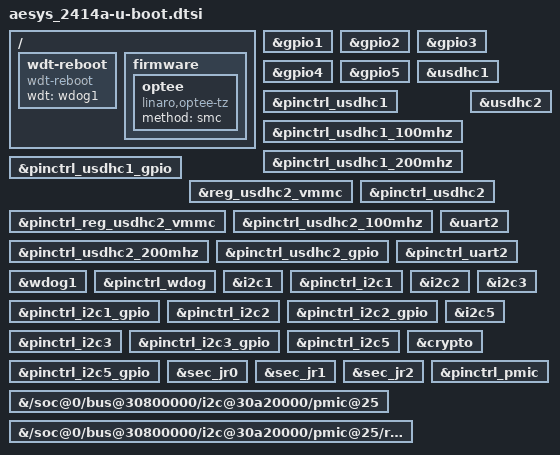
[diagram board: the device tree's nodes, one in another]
// SPDX-License-Identifier: GPL-2.0+

#include "imx8mp-sec-def.h"

#include "imx8mp-u-boot.dtsi"

/ {
	wdt-reboot {
		compatible = "wdt-reboot";
		wdt = <&wdog1>;
		bootph-pre-ram;
	};

	firmware {
		optee {
			compatible = "linaro,optee-tz";
			method = "smc";
		};
	};

	/* mcu_rdc {
		compatible = "imx8m,mcu_rdc";
			    * rdc config when MCU starts
			     * master
			     *   SDMA3p --> domain 1
			     *   SDMA3b --> domian 1
			     *   SDMA3_SPBA2  --> domian 1
			     * peripheral:
			     *   SAI3   --> Only Domian 1 can access
			     *   UART4  --> Only Domian 1 can access
			     *   GPT1   --> Only Domian 1 can access
			     *   SDMA3  --> Only Domian 1 can access
			     *   I2C3   --> Only Domian 1 can access
			     * memory:
			     *   TCM    --> Only Domian 1 can access (0x7E0000~0x81FFFF)
			     *   DDR    --> Only Domian 1 can access (0x80000000~0x81000000)
			     * end.
			     *
		start-config = <
			    RDC_MDA  RDC_MDA_SDMA3p DID1 0x0 0x0
			    RDC_MDA  RDC_MDA_ENET1_TX DID1 0x0 0x0
			    RDC_MDA  RDC_MDA_ENET1_RX DID1 0x0 0x0
			    RDC_MDA  RDC_MDA_SDMA3b DID1 0x0 0x0
			    RDC_MDA  RDC_MDA_SDMA3_SPBA2 DID1 0x0 0x0
			    RDC_PDAP RDC_PDAP_ENET1 PDAP_D0D1_ACCESS 0x0 0x0
			    RDC_PDAP RDC_PDAP_SAI3  PDAP_D1_ACCESS 0x0 0x0
			    RDC_PDAP RDC_PDAP_UART4 PDAP_D1_ACCESS 0x0 0x0
			    RDC_PDAP RDC_PDAP_GPT1  PDAP_D1_ACCESS 0x0 0x0
			    RDC_PDAP RDC_PDAP_SDMA3 PDAP_D1_ACCESS 0x0 0x0
			    RDC_PDAP RDC_PDAP_I2C3  PDAP_D1_ACCESS 0x0 0x0
			    RDC_MEM_REGION 22 TCM_START TCM_END MEM_D1_ACCESS
			    RDC_MEM_REGION 39 M4_DDR_START M4_DDR_END MEM_D1_ACCESS
			    0x0      0x0            0x0  0x0 0x0
			  >;
			     * rdc config when MCU stops
			     * memory:
			     *   TCM    --> domain 0/1 can access (0x7E0000~0x81FFFF)
			     *   DDR    --> domain 0/1 can access (0x80000000~0x81000000)
			     * end.
			     *
		stop-config = <
			    RDC_MEM_REGION 22 TCM_START TCM_END MEM_D0D1_ACCESS
			    RDC_MEM_REGION 39 M4_DDR_START M4_DDR_END MEM_D0D1_ACCESS
			    0x0      0x0            0x0  0x0 0x0
			  >;
	}; */
};

&gpio1 {
	bootph-pre-ram;
};

&gpio2 {
	bootph-pre-ram;
};

&gpio3 {
	bootph-pre-ram;
};

&gpio4 {
	bootph-pre-ram;
};

&gpio5 {
	bootph-pre-ram;
};

&usdhc1 {
	bootph-pre-ram;
};

&pinctrl_usdhc1 {
	bootph-pre-ram;
};

&pinctrl_usdhc1_100mhz {
	bootph-pre-ram;
};

&pinctrl_usdhc1_200mhz {
	bootph-pre-ram;
};

&pinctrl_usdhc1_gpio {
	bootph-pre-ram;
};

&usdhc2 {
	bootph-pre-ram;
};

&reg_usdhc2_vmmc {
	bootph-pre-ram;
};

&pinctrl_reg_usdhc2_vmmc {
	bootph-pre-ram;
};

&pinctrl_usdhc2 {
	bootph-pre-ram;
};

&pinctrl_usdhc2_100mhz {
	bootph-pre-ram;
};

&pinctrl_usdhc2_200mhz {
	bootph-pre-ram;
};

&pinctrl_usdhc2_gpio {
	bootph-pre-ram;
};

&uart2 {
	bootph-pre-ram;
};

&pinctrl_uart2 {
	bootph-pre-ram;
};

&wdog1 {
	bootph-pre-ram;
};

&pinctrl_wdog {
	bootph-pre-ram;
};

&i2c1 {
	bootph-pre-ram;
};

&pinctrl_i2c1 {
	bootph-pre-ram;
};

&pinctrl_i2c1_gpio {
	bootph-pre-ram;
};

&i2c2 {
	bootph-pre-ram;
};

&pinctrl_i2c2 {
	bootph-pre-ram;
};

&pinctrl_i2c2_gpio {
	bootph-pre-ram;
};

&i2c3 {
	bootph-pre-ram;
};

&pinctrl_i2c3 {
	bootph-pre-ram;
};

&pinctrl_i2c3_gpio {
	bootph-pre-ram;
};

&i2c5 {
	bootph-pre-ram;
};

&pinctrl_i2c5 {
	bootph-pre-ram;
};

&pinctrl_i2c5_gpio {
	bootph-pre-ram;
};

&crypto {
	bootph-pre-ram;
};

&sec_jr0 {
	bootph-pre-ram;
};

&sec_jr1 {
	bootph-pre-ram;
};

&sec_jr2 {
	bootph-pre-ram;
};

&{/soc@0/bus@30800000/i2c@30a20000/pmic@25} {
	bootph-pre-ram;
};

&{/soc@0/bus@30800000/i2c@30a20000/pmic@25/regulators} {
	bootph-pre-ram;
};

&pinctrl_pmic {
	bootph-pre-ram;
};

